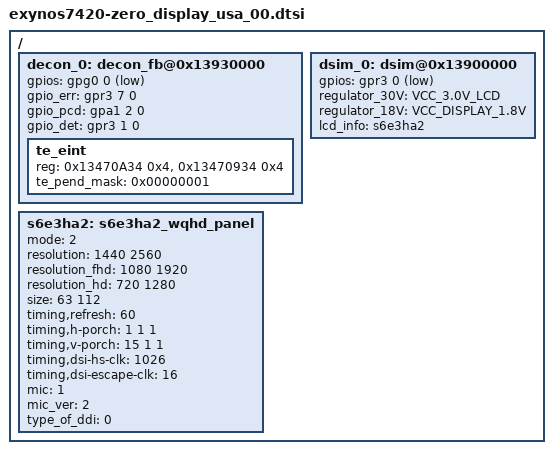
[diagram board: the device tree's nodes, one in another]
/ {
    decon_0: decon_fb@0x13930000 {
		/* EINT for TE */
		gpios = <&gpg0 0 0xf>;
		gpio_err = <&gpr3 7 0>;
		gpio_pcd = <&gpa1 2 0>;
		gpio_det = <&gpr3 1 0>;
		te_eint {
			reg = <0x13470A34 0x4>, <0x13470934 0x4>;
			te_pend_mask = <0x00000001>;
		};
	};

	dsim_0: dsim@0x13900000 {
		gpios = <&gpr3 0 0x1>;
		regulator_30V = "VCC_3.0V_LCD";
		regulator_18V = "VCC_DISPLAY_1.8V"; 
		lcd_info = <&s6e3ha2>;
	};

	s6e3ha2: s6e3ha2_wqhd_panel {
		mode = <2>;
		resolution = <1440 2560>;
		resolution_fhd  = <1080 1920>;
		resolution_hd = <720 1280>;
		size = <63 112>;
		timing,refresh = <60>;
		timing,h-porch = <1 1 1>;
		timing,v-porch = <15 1 1>;
		timing,dsi-hs-clk = <1026>;
		timing,dsi-escape-clk = <16>;
		mic = <1>;
		mic_ver = <2>;
		type_of_ddi = <0>;
	};
};
